# AVR32EB14 register map
Vendor: Atmel; File version: 1.0
CPU: other r0p0, little endian, no MPU, no FPU, 4 interrupt priority bits
Registers are 8-bit, read-write, reset 0x0 unless marked. A register's access mark holds for its fields unless they carry their own. Offsets are from the block's base; [hi:lo] are bit positions; {n}, {i} and the like mark numbered series; 'fields as' and 'values as' point back to an identical list.

## EVSYS — Event System
Base 0x00800200
0x00 SWEVENTA — Software Event A
  [7:0] SWEVENTA wo — Software event on channel select
    1=CH0 (Software event on channel 0); 2=CH1 (Software event on channel 1); 4=CH2 (Software event on channel 2); 8=CH3 (Software event on channel 3); 16=CH4 (Software event on channel 4); 32=CH5 (Software event on channel 5); 64=CH6 (Software event on channel 6); 128=CH7 (Software event on channel 7)
{0x10+i} CHANNEL{i} (i=0..5) — Multiplexer Channel {i}
  [7:0] CHANNEL — Channel generator select
    0=OFF; 1=UPDI_SYNCH (UPDI SYNCH character); 6=RTC_OVF (Real Time Counter overflow); 7=RTC_CMP (Real Time Counter compare); 8=RTC_PITEV0 (Periodic Interrupt Timer Event 0); 9=RTC_PITEV1 (Periodic Interrupt Timer Event 1); {v}=CCL_LUT{v-16} (Configurable Custom Logic LUT{v-16}) (v=16..19); 32=AC0_OUT (Analog Comparator 0 out); 33=AC1_OUT (Analog Comparator 1 out); 36=ADC0_RES (ADC 0 Result Ready); 37=ADC0_SAMP (ADC 0 Sample Ready); 38=ADC0_WCMP (ADC 0 Window Compare); 64=PORTA_EV0 (Port A Event 0); 65=PORTA_EV1 (Port A Event 1); 68=PORTC_EV0 (Port C Event 0); 69=PORTC_EV1 (Port C Event 1); 70=PORTD_EV0 (Port D Event 0); 71=PORTD_EV1 (Port D Event 1); 74=PORTF_EV0 (Port F Event 0); 75=PORTF_EV1 (Port F Event 1); 96=USART0_XCK; 104=SPI0_SCK; 128=TCE0_OVF (Timer/Counter E0 overflow); {v}=TCE0_CMP{v-132} (Timer/Counter E0 compare {v-132}) (v=132..135); 160=TCB0_CAPT (Timer/Counter B0 capture); 161=TCB0_OVF (Timer/Counter B0 overflow); 162=TCB1_CAPT (Timer/Counter B1 capture); 163=TCB1_OVF (Timer/Counter B1 overflow); 184=TCF0_OVF (Timer/Counter F0 Overflow); 185=TCF0_CMP0 (Timer/Counter F0 compare 0); 186=TCF0_CMP1 (Timer/Counter F0 compare 1)
{0x20+2i} USERCCLLUT{i}A (i=0..3) — CCL{i} Event A
  [7:0] USER — User channel select
    0=OFF (Off, No Eventsys Channel connected); {v}=CHANNEL{v-1} (Connect user to event channel {v-1}) (v=1..6)
{0x21+2i} USERCCLLUT{i}B (i=0..3) — CCL{i} Event B
  fields as USERCCLLUT0A
0x28 USERADC0START — ADC0 Start
  fields as USERCCLLUT0A
0x29 USEREVSYSEVOUTA — EVOUTA
  fields as USERCCLLUT0A
0x2A USEREVSYSEVOUTC — EVOUTC
  fields as USERCCLLUT0A
0x2B USEREVSYSEVOUTD — EVOUTD
  fields as USERCCLLUT0A
0x2C USEREVSYSEVOUTF — EVOUTF
  fields as USERCCLLUT0A
0x2D USERUSART0IRDA — USART0 IrDA Event
  fields as USERCCLLUT0A
0x2E USERTCE0CNTA — TCE0 Event A
  fields as USERCCLLUT0A
0x2F USERTCE0CNTB — TCE0 Event B
  fields as USERCCLLUT0A
0x30 USERTCB0CAPT — TCB0 Event A
  fields as USERCCLLUT0A
0x31 USERTCB0COUNT — TCB0 Event B
  fields as USERCCLLUT0A
0x32 USERTCB1CAPT — TCB1 Event A
  fields as USERCCLLUT0A
0x33 USERTCB1COUNT — TCB1 Event B
  fields as USERCCLLUT0A
0x34 USERTCF0CNT — TCF0 Clock Event
  fields as USERCCLLUT0A
0x35 USERTCF0ACT — TCF0 Action Event
  fields as USERCCLLUT0A
0x36 USERWEXA — WEX Event A
  fields as USERCCLLUT0A
0x37 USERWEXB — WEX Event B
  fields as USERCCLLUT0A
0x38 USERWEXC — WEX Event C
  fields as USERCCLLUT0A

## GPR — General Purpose Registers
Base 0x0080001C
{0x0+i} GPR{i} (i=0..3) — General Purpose Register {i}

## LOCK — Lockbits
Base 0x00801040
0x00 KEY 32-bit (reset mask 0xFF) — Lock Key Bits
  [31:0] KEY — Lock Key
    0x5CC5C55C=NOLOCK (No locks); 0xA33A3AA3=RWLOCK (Read and write lock)

## NVMCTRL — Non-volatile Memory Controller
Base 0x00801000
0x00 CTRLA — Control A
  [6:0] CMD — Command
    0=NOCMD (No Command); 1=NOOP (No Operation); 4=FLPW (Flash Page Write); 5=FLPERW (Flash Page Erase and Write); 8=FLPER (Flash Page Erase); 9=FLMPER2 (Flash 2-page erase enable); 10=FLMPER4 (Flash 4-page erase enable); 11=FLMPER8 (Flash 8-page erase enable); 12=FLMPER16 (Flash 16-page erase enable); 13=FLMPER32 (Flash 32-page erase enable); 15=FLPBCLR (Flash Page Buffer Clear); 20=EEPW (EEPROM Page Write); 21=EEPERW (EEPROM Page Erase and Write); 23=EEPER (EEPROM Page Erase); 31=EEPBCLR (EEPROM Page Buffer Clear); 32=CHER (Chip Erase Command (UPDI only)); 48=EECHER (EEPROM Erase Command (UPDI only))
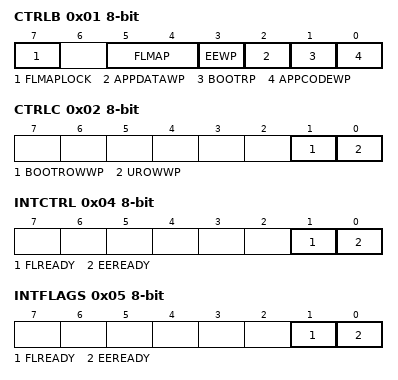
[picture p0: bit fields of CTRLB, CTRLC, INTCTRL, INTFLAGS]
0x01 CTRLB — Control B
  [7] FLMAPLOCK — Flash Mapping Lock
  [5:4] FLMAP — Flash Mapping in Data space
    0=SECTION0 (Flash section 0, 0 - 32KB); 1=SECTION1 (Flash section 1, 32 - 64KB); 2=SECTION2 (Flash section 2, 64 - 96KB); 3=SECTION3 (Flash section 3, 96 - 128KB)
  [3] EEWP — EEPROM Write Protect
  [2] APPDATAWP — Application Data Write Protect
  [1] BOOTRP — Boot Read Protect
  [0] APPCODEWP — Application Code Write Protect
0x02 CTRLC — Control C
  [1] BOOTROWWP — Boot Row Write Protect
  [0] UROWWP — User Row Write Protect
0x04 INTCTRL — Interrupt Control
  [1] FLREADY — Flash Ready
  [0] EEREADY — EEPROM Ready
0x05 INTFLAGS — Interrupt Flags
  [1] FLREADY — Flash Ready
  [0] EEREADY — EEPROM Ready
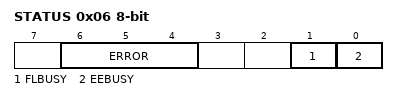
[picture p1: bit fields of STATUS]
0x06 STATUS
  [6:4] ERROR — Write error
    0=NOERROR; 2=WRITEPROTECT (Attempt to program write protected area); 3=CMDCOLLISION (Selecting new write command while write command already seleted); 4=WRONGSECTION (Address cannot be written with selected command)
  [1] FLBUSY ro — Flash busy
  [0] EEBUSY ro — EEPROM busy
0x08 DATA 16-bit (reset mask 0xFF)
0x0C ADDR 32-bit (reset mask 0xFF) — Address
  [23:0] ADDR
